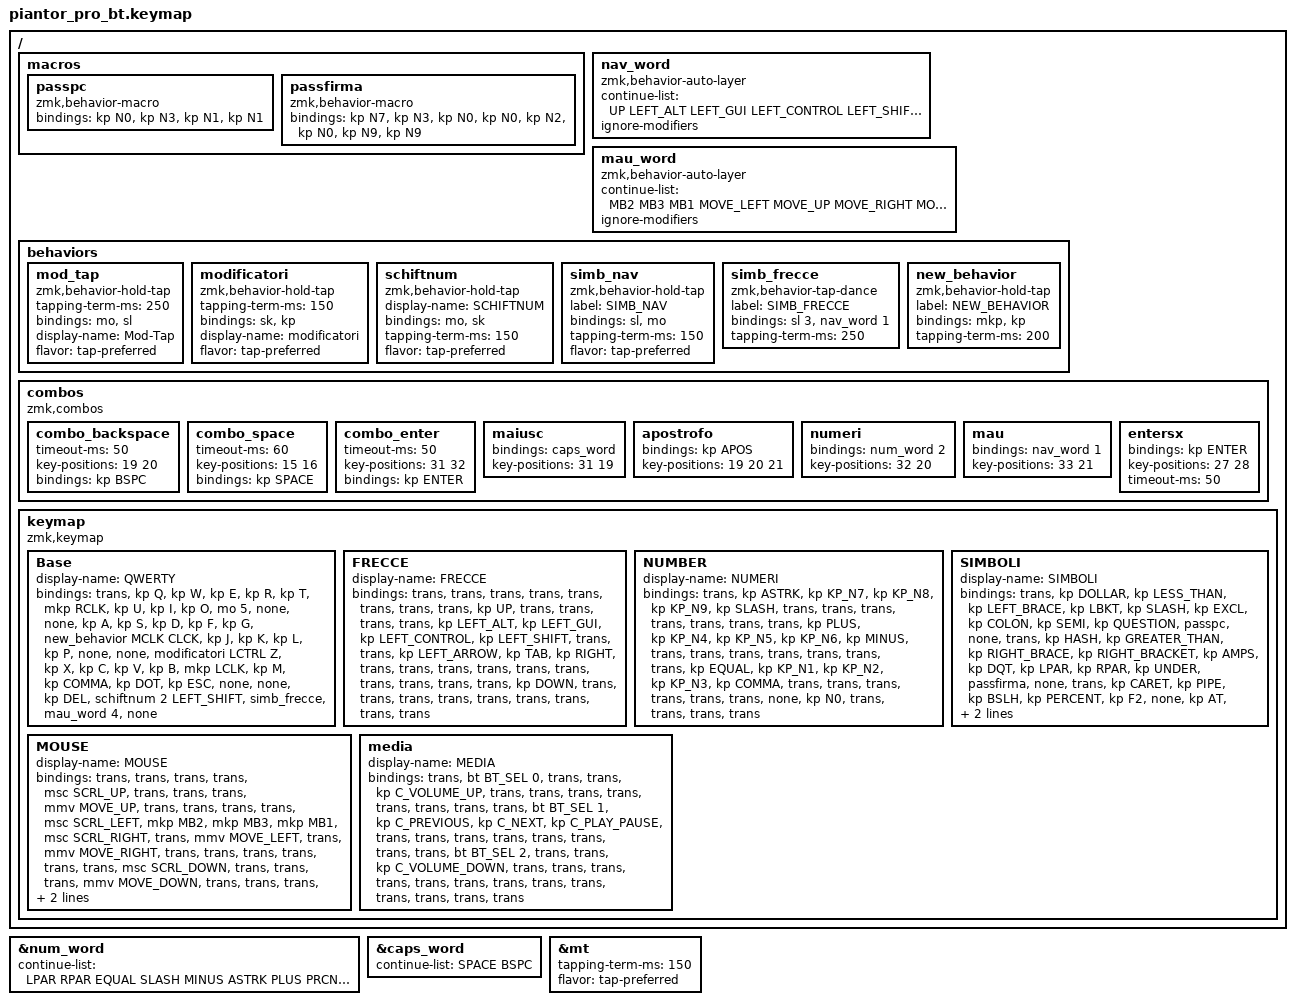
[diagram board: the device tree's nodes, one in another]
/*
 * Copyright (c) 2021-2022 The ZMK Contributors
 * SPDX-License-Identifier: MIT
 */

#define ZMK_POINTING_DEFAULT_MOVE_VAL 1200
#define ZMK_POINTING_DEFAULT_SCRL_VAL 30
#define MOUSE_TIME_TO_MAX_SPEED 300

#include <dt-bindings/zmk/behaviors.h>
#include <behaviors/num_word.dtsi>
#include <input/processors.dtsi>
#include "keys_it.h"
#include <behaviors.dtsi>
#include <dt-bindings/zmk/bt.h>
#include <dt-bindings/zmk/keys.h>
#include <dt-bindings/zmk/pointing.h>

&num_word { continue-list = <LPAR RPAR EQUAL SLASH MINUS ASTRK PLUS PRCNT COMMA DOT>; };

&caps_word { continue-list = <SPACE BSPC>; };

&mt {
    tapping-term-ms = <150>;
    flavor = "tap-preferred";
};

/ {
    macros {
        passpc: passpc {
            compatible = "zmk,behavior-macro";
            #binding-cells = <0>;
            bindings = <&kp N0 &kp N3 &kp N1 &kp N1>;
        };

        passfirma: passfirma {
            compatible = "zmk,behavior-macro";
            #binding-cells = <0>;
            bindings = <&kp N7 &kp N3 &kp N0 &kp N0 &kp N2 &kp N0 &kp N9 &kp N9>;
        };
    };

    nav_word: nav_word {
        compatible = "zmk,behavior-auto-layer";
        #binding-cells = <1>;
        continue-list = <UP LEFT_ALT LEFT_GUI LEFT_CONTROL LEFT_SHIFT LEFT RIGHT TAB DOWN>;
        ignore-modifiers;
    };

    mau_word: mau_word {
        compatible = "zmk,behavior-auto-layer";
        #binding-cells = <1>;
        continue-list = <MB2 MB3 MB1 MOVE_LEFT MOVE_UP MOVE_RIGHT MOVE_DOWN SCRL_UP SCRL_DOWN SCRL_RIGHT SCRL_LEFT>;
        ignore-modifiers;
    };

    behaviors {
        mod_tap: mod_tap {
            compatible = "zmk,behavior-hold-tap";
            #binding-cells = <2>;
            tapping-term-ms = <250>;
            bindings = <&mo>, <&sl>;

            display-name = "Mod-Tap";
            flavor = "tap-preferred";
        };

        modificatori: modificatori {
            compatible = "zmk,behavior-hold-tap";
            #binding-cells = <2>;
            tapping-term-ms = <150>;
            bindings = <&sk>, <&kp>;

            display-name = "modificatori";
            flavor = "tap-preferred";
        };

        schiftnum: schiftnum {
            compatible = "zmk,behavior-hold-tap";
            #binding-cells = <2>;
            display-name = "SCHIFTNUM";
            bindings = <&mo>, <&sk>;

            tapping-term-ms = <150>;
            flavor = "tap-preferred";
        };

        simb_nav: simb_nav {
            compatible = "zmk,behavior-hold-tap";
            label = "SIMB_NAV";
            bindings = <&sl>, <&mo>;

            #binding-cells = <2>;
            tapping-term-ms = <150>;
            flavor = "tap-preferred";
        };

        simb_frecce: simb_frecce {
            compatible = "zmk,behavior-tap-dance";
            label = "SIMB_FRECCE";
            #binding-cells = <0>;
            bindings = <&sl 3>, <&nav_word 1>;

            tapping-term-ms = <250>;
        };

        new_behavior: new_behavior {
            compatible = "zmk,behavior-hold-tap";
            label = "NEW_BEHAVIOR";
            bindings = <&mkp>, <&kp>;

            #binding-cells = <2>;
            tapping-term-ms = <200>;
        };
    };

    combos {
        compatible = "zmk,combos";

        combo_backspace {
            timeout-ms = <50>;
            key-positions = <19 20>;
            bindings = <&kp BSPC>;
        };

        combo_space {
            timeout-ms = <60>;
            key-positions = <15 16>;
            bindings = <&kp SPACE>;
        };

        combo_enter {
            timeout-ms = <50>;
            key-positions = <31 32>;
            bindings = <&kp ENTER>;
        };

        maiusc {
            bindings = <&caps_word>;
            key-positions = <31 19>;
        };

        apostrofo {
            bindings = <&kp APOS>;
            key-positions = <19 20 21>;
        };

        numeri {
            bindings = <&num_word 2>;
            key-positions = <32 20>;
        };

        mau {
            bindings = <&nav_word 1>;
            key-positions = <33 21>;
        };

        entersx {
            bindings = <&kp ENTER>;
            key-positions = <27 28>;
            timeout-ms = <50>;
        };
    };

    keymap {
        compatible = "zmk,keymap";

        Base {
            display-name = "QWERTY";
            bindings = <
&trans  &kp Q  &kp W  &kp E  &kp R  &kp T  &mkp RCLK  &kp U  &kp I  &kp O  &mo 5  &none  &none  &kp A  &kp S  &kp D  &kp F  &kp G  &new_behavior MCLK CLCK  &kp J  &kp K  &kp L  &kp P  &none  &none  &modificatori LCTRL Z  &kp X  &kp C  &kp V  &kp B  &mkp LCLK  &kp M  &kp COMMA  &kp DOT  &kp ESC  &none  &none  &kp DEL  &schiftnum 2 LEFT_SHIFT  &simb_frecce  &mau_word 4  &none
            >;
        };

        FRECCE {
            display-name = "FRECCE";
            bindings = <
&trans  &trans  &trans  &trans  &trans  &trans  &trans  &trans  &kp UP  &trans  &trans  &trans  &trans  &kp LEFT_ALT  &kp LEFT_GUI  &kp LEFT_CONTROL  &kp LEFT_SHIFT  &trans  &trans  &kp LEFT_ARROW  &kp TAB  &kp RIGHT  &trans  &trans  &trans  &trans  &trans  &trans  &trans  &trans  &trans  &trans  &kp DOWN  &trans  &trans  &trans  &trans  &trans  &trans  &trans  &trans  &trans
            >;
        };

        NUMBER {
            display-name = "NUMERI";
            bindings = <
&trans  &kp ASTRK  &kp KP_N7  &kp KP_N8  &kp KP_N9  &kp SLASH  &trans  &trans  &trans  &trans  &trans  &trans  &trans  &kp PLUS  &kp KP_N4  &kp KP_N5  &kp KP_N6  &kp MINUS  &trans  &trans  &trans  &trans  &trans  &trans  &trans  &kp EQUAL  &kp KP_N1  &kp KP_N2  &kp KP_N3  &kp COMMA  &trans  &trans  &trans  &trans  &trans  &trans  &none  &kp N0  &trans  &trans  &trans  &trans
            >;
        };

        SIMBOLI {
            display-name = "SIMBOLI";
            bindings = <
&trans  &kp DOLLAR  &kp LESS_THAN  &kp LEFT_BRACE  &kp LBKT  &kp SLASH  &kp EXCL  &kp COLON  &kp SEMI  &kp QUESTION  &passpc  &none  &trans  &kp HASH  &kp GREATER_THAN  &kp RIGHT_BRACE  &kp RIGHT_BRACKET  &kp AMPS  &kp DQT  &kp LPAR  &kp RPAR  &kp UNDER  &passfirma  &none  &trans  &kp CARET  &kp PIPE  &kp BSLH  &kp PERCENT  &kp F2  &none  &kp AT  &kp HOME  &none  &kp PRINTSCREEN  &none  &trans  &trans  &trans  &trans  &trans  &trans
            >;
        };

        MOUSE {
            display-name = "MOUSE";
            bindings = <
&trans  &trans  &trans  &trans  &msc SCRL_UP  &trans  &trans  &trans  &mmv MOVE_UP  &trans  &trans  &trans  &trans  &msc SCRL_LEFT  &mkp MB2  &mkp MB3  &mkp MB1  &msc SCRL_RIGHT  &trans  &mmv MOVE_LEFT  &trans  &mmv MOVE_RIGHT  &trans  &trans  &trans  &trans  &trans  &trans  &msc SCRL_DOWN  &trans  &trans  &trans  &mmv MOVE_DOWN  &trans  &trans  &trans  &trans  &none  &none  &mmv MOVE_DOWN  &trans  &trans
            >;
        };

        media {
            display-name = "MEDIA";
            bindings = <
&trans  &bt BT_SEL 0  &trans  &trans  &kp C_VOLUME_UP  &trans  &trans  &trans  &trans  &trans  &trans  &trans  &trans  &bt BT_SEL 1  &kp C_PREVIOUS  &kp C_NEXT  &kp C_PLAY_PAUSE  &trans  &trans  &trans  &trans  &trans  &trans  &trans  &trans  &bt BT_SEL 2  &trans  &trans  &kp C_VOLUME_DOWN  &trans  &trans  &trans  &trans  &trans  &trans  &trans  &trans  &trans  &trans  &trans  &trans  &trans
            >;
        };
    };
};
